# NUC2201AE_v1 register map
File version: 1.0
NUC2201AE_v1 SVD file
Registers are 32-bit, read-write, reset 0x0 unless marked. A register's access mark holds for its fields unless they carry their own. Offsets are from the block's base; lines under a group give offsets from that group; [hi:lo] are bit positions; {n}, {i} and the like mark numbered series; 'fields as' and 'values as' point back to an identical list; <NAME> marks a mode.

## Memory map
0x40004000 WDT size 0x8 — WDT Register Map
0x40004100 WWDT size 0x10 — WWDT Register Map
0x40008000 RTC blocks up to offset 0x90 — RTC Register Map
0x40010000 TMR01 blocks up to offset 0x3C — TIMER Register Map
0x40012000 I2C1 blocks up to offset 0x44 — I2C Register Map
0x40020000 I2C0 blocks up to offset 0x44 — I2C Register Map
0x40030000 SPI0 blocks up to offset 0x48 — SPI Register Map
0x40034000 SPI1 blocks up to offset 0x48 — SPI Register Map
0x40040000 PWMA blocks up to offset 0x98 — PWM Register Map
0x40050000 UART0 size 0x3C — UART Register Map
0x40060000 USBD blocks up to offset 0x580 — USB Register Map
0x400E0000 ADC blocks up to offset 0x60 — ADC Register Map
0x40110000 TMR23 blocks up to offset 0x3C — TIMER Register Map
0x40140000 PWMB blocks up to offset 0x90 — PWM Register Map
0x40150000 UART1 size 0x3C — UART Register Map
0x40154000 UART2 blocks up to offset 0x3C — UART Register Map
0x50000000 GCR blocks up to offset 0x104 — GCR Register Map
0x50000200 CLK size 0x28 — CLK Register Map
0x50000300 INT size 0x8C — INT Register Map
0x50004000 GPIO blocks up to offset 0x350 — GPIO Register Map
{0x50008000+0x100*n} PDMA_CH{n} blocks up to offset 0x84 (n=0..8) — PDMA Register Map
0x50008E00 CRC blocks up to offset 0x8C — PDMA Register Map
0x50008F00 PDMA_GCR size 0x10 — PDMA Register Map
0x5000C000 FMC blocks up to offset 0x44 — FMC Register Map
0x50010000 EBI size 0xC — EBI Register Map
0xE000E000 SCS blocks up to offset 0xD24 — SYST_NVIC_SCS Register Map

## EBI — EBI Register Map
Base 0x50010000
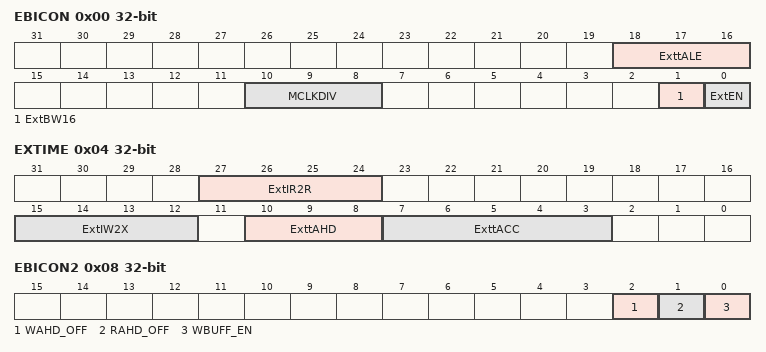
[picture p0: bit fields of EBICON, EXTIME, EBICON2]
0x00 EBICON — External Bus Interface General Control Register
  [18:16] ExttALE — Expand Time of ALE. This field is used for control the ALE pulse width (tALE) for latch the address
  [10:8] MCLKDIV — External Output Clock Divider
  [1] ExtBW16 — EBI Data Width 16-bit/8-bit. This bit defines if the data bus is 8-bit or 16-bit.
    0=EBI data width is 8-bit; 1=EBI data width is 16-bit
  [0] ExtEN — EBI Enable. This bit is the functional enable bit for EBI.
    0=EBI function Disabled; 1=EBI function Enabled
0x04 EXTIME — External Bus Interface Timing Control Register
  [27:24] ExtIR2R — Idle State Cycle Between Read-Read. When read action is finished and the next action is going to read, idle state is inserted and nCS signal return to high if ExtIR2R is not zero.
  [15:12] ExtIW2X — Idle State Cycle After Write. When write action is finished, idle state is inserted and nCS signal return to high if ExtIW2X is not zero.
  [10:8] ExttAHD — EBI Data Access Hold Time. ExttAHD defines data access hold time (tAHD).
  [7:3] ExttACC — EBI Data Access Time. ExttACC defines data access time (tACC).
0x08 EBICON2 — External Bus Interface General Control Register 2
  [2] WAHD_OFF — Access Hold Time Disable Control When Write
    0=tAHD is controlled by ExttAHD when write through EBI; 1=No tAHD when write through EBI
  [1] RAHD_OFF — Access Hold Time Disable Control When Read
    0=tAHD is controlled by ExttAHD when read through EBI; 1=No tAHD when read through EBI
  [0] WBUFF_EN — EBI Write Buffer Enable
    0=EBI write buffer disable; 1=EBI write buffer enable

## WWDT — WWDT Register Map
Base 0x40004100
0x00 WWDTRLD wo — Window Watchdog Timer Reload Counter Register
  [31:0] WWDTRLD — WWDT Reload Counter Register. Writing 0x00005AA5 to this register will reload the WWDT counter value to 0x3F. Note: User can only write WWDTRLD to reload WWDT counter value when current WWDT counter value between 0 and WINCMP. If user writes WWDTRLD when current WWDT counter value is larger than WINCMP, WWDT reset signal will generate immediately.
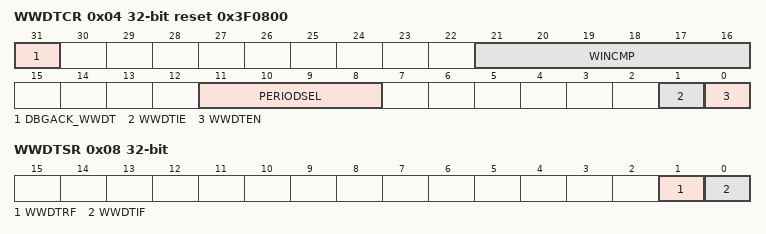
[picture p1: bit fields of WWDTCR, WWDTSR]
0x04 WWDTCR reset 0x3F0800 — Window Watchdog Timer Control Register
  [31] DBGACK_WWDT — ICE Debug Mode Acknowledge Disable Bit. WWDT down counter will keep going no matter CPU is held by ICE or not.
    0=ICE debug mode acknowledgement effects WWDT counting; 1=ICE debug mode acknowledgement Disabled
  [21:16] WINCMP — WWDT Window Compare Register. Set this register to adjust the valid reload window. Note: User can only write WWDTRLD to reload WWDT counter value when current WWDT counter value between 0 and WINCMP. If user writes WWDTRLD when current WWDT counter value larger than WINCMP, WWDT reset signal will generate immediately.
  [11:8] PERIODSEL — WWDT Counter Prescale Period Selection
    0=Pre-scale is 1; Max time-out period is 1 * 64 * TWWDT; 1=Pre-scale is 2; Max time-out period is 2 * 64 * TWWDT; 2=Pre-scale is 4; Max time-out period is 4 * 64 * TWWDT; 3=Pre-scale is 8; Max time-out period is 8 * 64 * TWWDT; 4=Pre-scale is 16; Max time-out period is 16 * 64 * TWWDT; 5=Pre-scale is 32; Max time-out period is 32 * 64 * TWWDT; 6=Pre-scale is 64; Max time-out period is 64 * 64 * TWWDT; 7=Pre-scale is 128; Max time-out period is 128 * 64 * TWWDT; 8=Pre-scale is 192; Max time-out period is 192 * 64 * TWWDT; 9=Pre-scale is 256; Max time-out period is 256 * 64 * TWWDT; 10=Pre-scale is 384; Max time-out period is 384 * 64 * TWWDT; 11=Pre-scale is 512; Max time-out period is 512 * 64 * TWWDT; 12=Pre-scale is 768; Max time-out period is 768 * 64 * TWWDT; 13=Pre-scale is 1024; Max time-out period is 1024 * 64 * TWWDT; 14=Pre-scale is 1536; Max time-out period is 1536 * 64 * TWWDT; 15=Pre-scale is 2048; Max time-out period is 2048 * 64 * TWWDT
  [1] WWDTIE — WWDT Interrupt Enable Bit. If this bit is enabled, the WWDT counter compare match interrupt signal is generated and inform to CPU.
    0=WWDT counter compare match interrupt Disabled; 1=WWDT counter compare match interrupt Enabled
  [0] WWDTEN — WWDT Enable Bit. Set this bit to enable WWDT counter counting
    0=WWDT counter is stopped; 1=WWDT counter is starting counting
0x08 WWDTSR — Window Watchdog Timer Status Register
  [1] WWDTRF — WWDT Time-Out Reset Flag. This bit indicates the system has been reset by WWDT time-out reset or not. Note: This bit is cleared by writing 1 to it.
    0=WWDT time-out reset did not occur; 1=WWDT time-out reset occurred
  [0] WWDTIF — WWDT Compare Match Interrupt Flag. This bit indicates the interrupt flag status of WWDT while WWDT counter value matches WINCMP value. Note: This bit is cleared by writing 1 to it.
    0=No effect; 1=WWDT counter value matches WINCMP value
0x0C WWDTCVR ro reset 0x3F — Window Watchdog Timer Counter Value Register
  [5:0] WWDTCVAL — WWDT Counter Value. WWDTCVAL will be updated continuously to monitor 6-bit down counter value.
